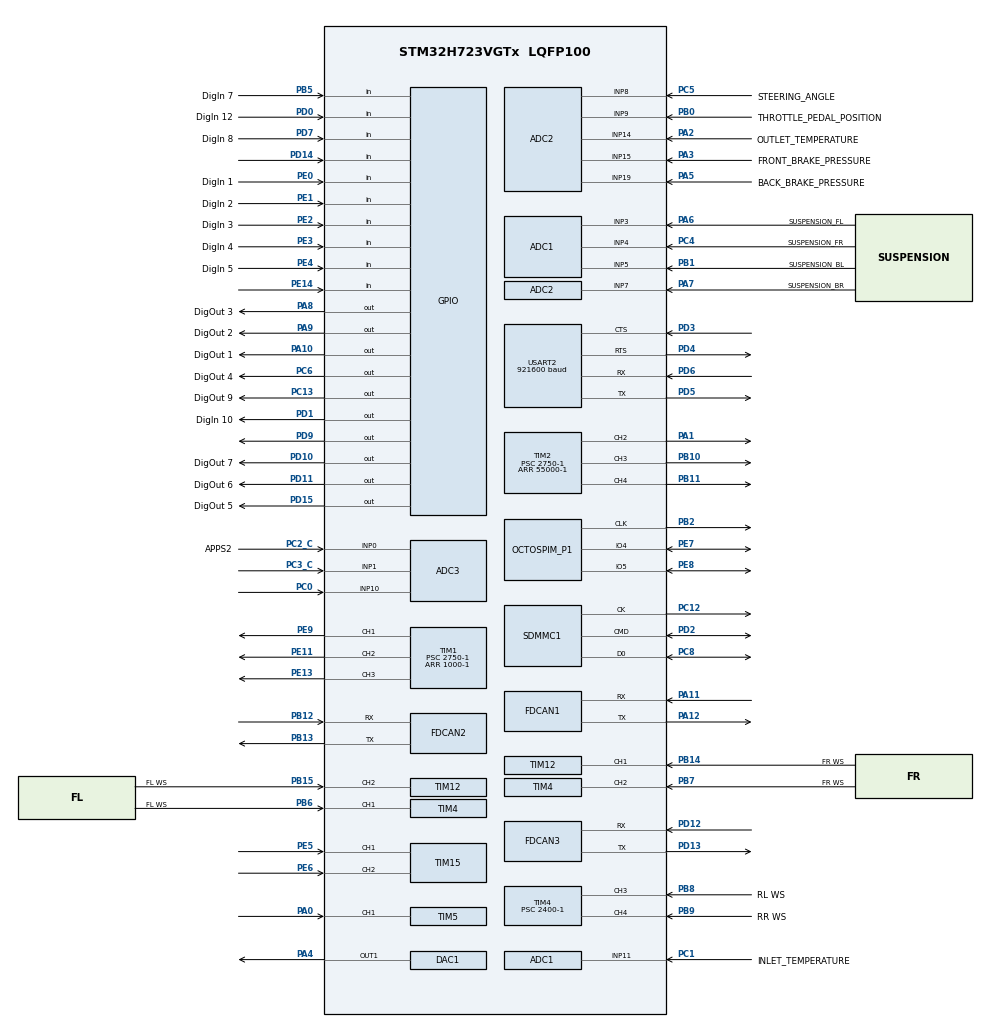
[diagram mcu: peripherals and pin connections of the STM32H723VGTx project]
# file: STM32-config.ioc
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ADC1.Channel-0\#ChannelRegularConversion=ADC_CHANNEL_3
ADC1.Channel-1\#ChannelRegularConversion=ADC_CHANNEL_4
ADC1.Channel-2\#ChannelRegularConversion=ADC_CHANNEL_5
ADC1.Channel-3\#ChannelRegularConversion=ADC_CHANNEL_7
ADC1.Channel-4\#ChannelRegularConversion=ADC_CHANNEL_8
ADC1.Channel-5\#ChannelRegularConversion=ADC_CHANNEL_9
ADC1.Channel-6\#ChannelRegularConversion=ADC_CHANNEL_11
ADC1.Channel-7\#ChannelRegularConversion=ADC_CHANNEL_14
ADC1.Channel-8\#ChannelRegularConversion=ADC_CHANNEL_15
ADC1.Channel-9\#ChannelRegularConversion=ADC_CHANNEL_19
ADC1.ClockPrescaler=ADC_CLOCK_SYNC_PCLK_DIV4
ADC1.ContinuousConvMode=DISABLE
ADC1.ConversionDataManagement=ADC_CONVERSIONDATA_DMA_ONESHOT
ADC1.DMAAccessModeView=ENABLE
ADC1.ExternalTrigConv=ADC_EXTERNALTRIG_T1_TRGO
ADC1.Mode=ADC_DUALMODE_REGSIMULT
ADC1.NbrOfConversion=10
ADC1.NbrOfConversionFlag=1
ADC1.OffsetNumber-0\#ChannelRegularConversion=ADC_OFFSET_NONE
ADC1.OffsetNumber-1\#ChannelRegularConversion=ADC_OFFSET_NONE
ADC1.OffsetNumber-2\#ChannelRegularConversion=ADC_OFFSET_NONE
ADC1.OffsetNumber-3\#ChannelRegularConversion=ADC_OFFSET_NONE
ADC1.OffsetNumber-4\#ChannelRegularConversion=ADC_OFFSET_NONE
ADC1.OffsetNumber-5\#ChannelRegularConversion=ADC_OFFSET_NONE
ADC1.OffsetNumber-6\#ChannelRegularConversion=ADC_OFFSET_NONE
ADC1.OffsetNumber-7\#ChannelRegularConversion=ADC_OFFSET_NONE
ADC1.OffsetNumber-8\#ChannelRegularConversion=ADC_OFFSET_NONE
ADC1.OffsetNumber-9\#ChannelRegularConversion=ADC_OFFSET_NONE
ADC1.OffsetSignedSaturation-0\#ChannelRegularConversion=DISABLE
ADC1.OffsetSignedSaturation-1\#ChannelRegularConversion=DISABLE
ADC1.OffsetSignedSaturation-2\#ChannelRegularConversion=DISABLE
ADC1.OffsetSignedSaturation-3\#ChannelRegularConversion=DISABLE
ADC1.OffsetSignedSaturation-4\#ChannelRegularConversion=DISABLE
ADC1.OffsetSignedSaturation-5\#ChannelRegularConversion=DISABLE
ADC1.OffsetSignedSaturation-6\#ChannelRegularConversion=DISABLE
ADC1.OffsetSignedSaturation-7\#ChannelRegularConversion=DISABLE
ADC1.OffsetSignedSaturation-8\#ChannelRegularConversion=DISABLE
ADC1.OffsetSignedSaturation-9\#ChannelRegularConversion=DISABLE
ADC1.OversamplingMode=DISABLE
ADC1.Rank-0\#ChannelRegularConversion=1
ADC1.Rank-1\#ChannelRegularConversion=2
ADC1.Rank-2\#ChannelRegularConversion=3
ADC1.Rank-3\#ChannelRegularConversion=4
ADC1.Rank-4\#ChannelRegularConversion=5
ADC1.Rank-5\#ChannelRegularConversion=6
ADC1.Rank-6\#ChannelRegularConversion=7
ADC1.Rank-7\#ChannelRegularConversion=8
ADC1.Rank-8\#ChannelRegularConversion=9
ADC1.Rank-9\#ChannelRegularConversion=10
ADC1.Ratio=1
ADC1.SamplingTime-0\#ChannelRegularConversion=ADC_SAMPLETIME_387CYCLES_5
ADC1.SamplingTime-1\#ChannelRegularConversion=ADC_SAMPLETIME_387CYCLES_5
ADC1.SamplingTime-2\#ChannelRegularConversion=ADC_SAMPLETIME_387CYCLES_5
ADC1.SamplingTime-3\#ChannelRegularConversion=ADC_SAMPLETIME_387CYCLES_5
ADC1.SamplingTime-4\#ChannelRegularConversion=ADC_SAMPLETIME_387CYCLES_5
ADC1.SamplingTime-5\#ChannelRegularConversion=ADC_SAMPLETIME_387CYCLES_5
ADC1.SamplingTime-6\#ChannelRegularConversion=ADC_SAMPLETIME_387CYCLES_5
ADC1.SamplingTime-7\#ChannelRegularConversion=ADC_SAMPLETIME_387CYCLES_5
ADC1.SamplingTime-8\#ChannelRegularConversion=ADC_SAMPLETIME_387CYCLES_5
ADC1.SamplingTime-9\#ChannelRegularConversion=ADC_SAMPLETIME_387CYCLES_5
ADC1.master=1
ADC2.Channel-0\#ChannelRegularConversion=ADC_CHANNEL_3
ADC2.Channel-1\#ChannelRegularConversion=ADC_CHANNEL_4
ADC2.Channel-2\#ChannelRegularConversion=ADC_CHANNEL_5
ADC2.Channel-3\#ChannelRegularConversion=ADC_CHANNEL_7
ADC2.Channel-4\#ChannelRegularConversion=ADC_CHANNEL_8
ADC2.Channel-5\#ChannelRegularConversion=ADC_CHANNEL_9
ADC2.Channel-6\#ChannelRegularConversion=ADC_CHANNEL_11
ADC2.Channel-7\#ChannelRegularConversion=ADC_CHANNEL_14
ADC2.Channel-8\#ChannelRegularConversion=ADC_CHANNEL_15
ADC2.Channel-9\#ChannelRegularConversion=ADC_CHANNEL_19
ADC2.ClockPrescaler=ADC_CLOCK_SYNC_PCLK_DIV4
ADC2.ContinuousConvMode=DISABLE
ADC2.ConversionDataManagement=ADC_CONVERSIONDATA_DR
ADC2.DMAAccessModeView=ENABLE
ADC2.Mode=ADC_DUALMODE_REGSIMULT
ADC2.NbrOfConversion=10
ADC2.NbrOfConversionFlag=1
ADC2.OffsetNumber-0\#ChannelRegularConversion=ADC_OFFSET_NONE
ADC2.OffsetNumber-1\#ChannelRegularConversion=ADC_OFFSET_NONE
ADC2.OffsetNumber-2\#ChannelRegularConversion=ADC_OFFSET_NONE
ADC2.OffsetNumber-3\#ChannelRegularConversion=ADC_OFFSET_NONE
ADC2.OffsetNumber-4\#ChannelRegularConversion=ADC_OFFSET_NONE
ADC2.OffsetNumber-5\#ChannelRegularConversion=ADC_OFFSET_NONE
ADC2.OffsetNumber-6\#ChannelRegularConversion=ADC_OFFSET_NONE
ADC2.OffsetNumber-7\#ChannelRegularConversion=ADC_OFFSET_NONE
ADC2.OffsetNumber-8\#ChannelRegularConversion=ADC_OFFSET_NONE
ADC2.OffsetNumber-9\#ChannelRegularConversion=ADC_OFFSET_NONE
ADC2.OffsetSignedSaturation-0\#ChannelRegularConversion=DISABLE
ADC2.OffsetSignedSaturation-1\#ChannelRegularConversion=DISABLE
ADC2.OffsetSignedSaturation-2\#ChannelRegularConversion=DISABLE
ADC2.OffsetSignedSaturation-3\#ChannelRegularConversion=DISABLE
ADC2.OffsetSignedSaturation-4\#ChannelRegularConversion=DISABLE
ADC2.OffsetSignedSaturation-5\#ChannelRegularConversion=DISABLE
ADC2.OffsetSignedSaturation-6\#ChannelRegularConversion=DISABLE
ADC2.OffsetSignedSaturation-7\#ChannelRegularConversion=DISABLE
ADC2.OffsetSignedSaturation-8\#ChannelRegularConversion=DISABLE
ADC2.OffsetSignedSaturation-9\#ChannelRegularConversion=DISABLE
ADC2.Rank-0\#ChannelRegularConversion=1
ADC2.Rank-1\#ChannelRegularConversion=2
ADC2.Rank-2\#ChannelRegularConversion=3
ADC2.Rank-3\#ChannelRegularConversion=4
ADC2.Rank-4\#ChannelRegularConversion=5
ADC2.Rank-5\#ChannelRegularConversion=6
ADC2.Rank-6\#ChannelRegularConversion=7
ADC2.Rank-7\#ChannelRegularConversion=8
ADC2.Rank-8\#ChannelRegularConversion=9
ADC2.Rank-9\#ChannelRegularConversion=10
ADC2.SamplingTime-0\#ChannelRegularConversion=ADC_SAMPLETIME_387CYCLES_5
ADC2.SamplingTime-1\#ChannelRegularConversion=ADC_SAMPLETIME_387CYCLES_5
ADC2.SamplingTime-2\#ChannelRegularConversion=ADC_SAMPLETIME_387CYCLES_5
ADC2.SamplingTime-3\#ChannelRegularConversion=ADC_SAMPLETIME_387CYCLES_5
ADC2.SamplingTime-4\#ChannelRegularConversion=ADC_SAMPLETIME_387CYCLES_5
ADC2.SamplingTime-5\#ChannelRegularConversion=ADC_SAMPLETIME_387CYCLES_5
ADC2.SamplingTime-6\#ChannelRegularConversion=ADC_SAMPLETIME_387CYCLES_5
ADC2.SamplingTime-7\#ChannelRegularConversion=ADC_SAMPLETIME_387CYCLES_5
ADC2.SamplingTime-8\#ChannelRegularConversion=ADC_SAMPLETIME_387CYCLES_5
ADC2.SamplingTime-9\#ChannelRegularConversion=ADC_SAMPLETIME_387CYCLES_5
ADC3.Channel-0\#ChannelRegularConversion=ADC_CHANNEL_0
ADC3.ClockPrescaler=ADC_CLOCK_SYNC_PCLK_DIV4
ADC3.ConversionDataManagement=ADC_CONVERSIONDATA_DMA_ONESHOT
ADC3.ExternalTrigConv=ADC_EXTERNALTRIG_T1_TRGO
ADC3.NbrOfConversion=1
ADC3.NbrOfConversionFlag=1
ADC3.OffsetNumber-0\#ChannelRegularConversion=ADC_OFFSET_NONE
ADC3.OffsetSign-0\#ChannelRegularConversion=ADC3_OFFSET_SIGN_NEGATIVE
ADC3.Rank-0\#ChannelRegularConversion=1
ADC3.SamplingTime-0\#ChannelRegularConversion=ADC3_SAMPLETIME_247CYCLES_5
Bdma.ADC3.0.Direction=DMA_PERIPH_TO_MEMORY
Bdma.ADC3.0.EventEnable=DISABLE
Bdma.ADC3.0.Instance=BDMA_Channel0
Bdma.ADC3.0.MemDataAlignment=DMA_MDATAALIGN_HALFWORD
Bdma.ADC3.0.MemInc=DMA_MINC_ENABLE
Bdma.ADC3.0.Mode=DMA_NORMAL
Bdma.ADC3.0.PeriphDataAlignment=DMA_PDATAALIGN_HALFWORD
Bdma.ADC3.0.PeriphInc=DMA_PINC_DISABLE
Bdma.ADC3.0.Polarity=HAL_DMAMUX_REQ_GEN_RISING
Bdma.ADC3.0.Priority=DMA_PRIORITY_LOW
Bdma.ADC3.0.RequestNumber=1
Bdma.ADC3.0.SignalID=NONE
Bdma.ADC3.0.SyncEnable=DISABLE
Bdma.ADC3.0.SyncPolarity=HAL_DMAMUX_SYNC_NO_EVENT
Bdma.ADC3.0.SyncRequestNumber=1
Bdma.ADC3.0.SyncSignalID=NONE
Bdma.Request0=ADC3
Bdma.RequestsNb=1
CORTEX_M7.AccessPermission_Spec=MPU_REGION_FULL_ACCESS
CORTEX_M7.IsCacheable_Spec=MPU_ACCESS_CACHEABLE
CORTEX_M7.default_mode_Activation=1
DAC1.DAC_Channel-DAC_OUT1=DAC_CHANNEL_1
Dma.ADC1.0.Direction=DMA_PERIPH_TO_MEMORY
Dma.ADC1.0.EventEnable=DISABLE
Dma.ADC1.0.FIFOMode=DMA_FIFOMODE_DISABLE
Dma.ADC1.0.Instance=DMA1_Stream0
Dma.ADC1.0.MemDataAlignment=DMA_MDATAALIGN_WORD
Dma.ADC1.0.MemInc=DMA_MINC_ENABLE
Dma.ADC1.0.Mode=DMA_NORMAL
Dma.ADC1.0.PeriphDataAlignment=DMA_PDATAALIGN_WORD
Dma.ADC1.0.PeriphInc=DMA_PINC_DISABLE
Dma.ADC1.0.Polarity=HAL_DMAMUX_REQ_GEN_RISING
Dma.ADC1.0.Priority=DMA_PRIORITY_LOW
Dma.ADC1.0.RequestNumber=1
Dma.ADC1.0.SignalID=NONE
Dma.ADC1.0.SyncEnable=DISABLE
Dma.ADC1.0.SyncPolarity=HAL_DMAMUX_SYNC_NO_EVENT
Dma.ADC1.0.SyncRequestNumber=1
Dma.ADC1.0.SyncSignalID=NONE
Dma.Request0=ADC1
Dma.Request1=USART2_TX
Dma.Request2=USART2_RX
Dma.USART2_RX.2.Direction=DMA_PERIPH_TO_MEMORY
Dma.USART2_RX.2.EventEnable=DISABLE
Dma.USART2_RX.2.FIFOMode=DMA_FIFOMODE_DISABLE
Dma.USART2_RX.2.Instance=DMA2_Stream1
Dma.USART2_RX.2.MemDataAlignment=DMA_MDATAALIGN_BYTE
Dma.USART2_RX.2.MemInc=DMA_MINC_ENABLE
Dma.USART2_RX.2.Mode=DMA_NORMAL
Dma.USART2_RX.2.PeriphDataAlignment=DMA_PDATAALIGN_BYTE
Dma.USART2_RX.2.PeriphInc=DMA_PINC_DISABLE
Dma.USART2_RX.2.Polarity=HAL_DMAMUX_REQ_GEN_RISING
Dma.USART2_RX.2.Priority=DMA_PRIORITY_LOW
Dma.USART2_RX.2.RequestNumber=1
Dma.USART2_RX.2.SignalID=NONE
Dma.USART2_RX.2.SyncEnable=DISABLE
Dma.USART2_RX.2.SyncPolarity=HAL_DMAMUX_SYNC_NO_EVENT
Dma.USART2_RX.2.SyncRequestNumber=1
Dma.USART2_RX.2.SyncSignalID=NONE
Dma.USART2_TX.1.Direction=DMA_MEMORY_TO_PERIPH
Dma.USART2_TX.1.EventEnable=DISABLE
Dma.USART2_TX.1.FIFOMode=DMA_FIFOMODE_DISABLE
Dma.USART2_TX.1.Instance=DMA2_Stream0
Dma.USART2_TX.1.MemDataAlignment=DMA_MDATAALIGN_BYTE
Dma.USART2_TX.1.MemInc=DMA_MINC_ENABLE
Dma.USART2_TX.1.Mode=DMA_CIRCULAR
Dma.USART2_TX.1.PeriphDataAlignment=DMA_PDATAALIGN_BYTE
Dma.USART2_TX.1.PeriphInc=DMA_PINC_DISABLE
Dma.USART2_TX.1.Polarity=HAL_DMAMUX_REQ_GEN_RISING
Dma.USART2_TX.1.Priority=DMA_PRIORITY_LOW
Dma.USART2_TX.1.RequestNumber=1
Dma.USART2_TX.1.SignalID=NONE
Dma.USART2_TX.1.SyncEnable=DISABLE
Dma.USART2_TX.1.SyncPolarity=HAL_DMAMUX_SYNC_NO_EVENT
Dma.USART2_TX.1.SyncRequestNumber=1
Dma.USART2_TX.1.SyncSignalID=NONE
FATFS.BSP.number=1
FATFS._FS_EXFAT=1
FATFS._FS_RPATH=1
FATFS._MAX_SS=512
FATFS._MIN_SS=512
FATFS._USE_CHMOD=1
FATFS._USE_EXPAND=1
FATFS._USE_FIND=1
FATFS._USE_FORWARD=1
FATFS._USE_LABEL=1
FATFS._USE_LFN=2
FATFS0.BSP.STBoard=false
FATFS0.BSP.api=Unknown
FATFS0.BSP.instance=PE14
FATFS0.BSP.ip=GPIO
FATFS0.BSP.mode=Input
FATFS0.BSP.name=Detect_SDIO
FATFS0.BSP.solution=PE14
FDCAN1.AutoRetransmission=ENABLE
FDCAN1.CalculateBaudRateNominal=500000
FDCAN1.CalculateTimeBitNominal=2000
FDCAN1.CalculateTimeQuantumNominal=125.0
FDCAN1.NominalPrescaler=10
FDCAN1.NominalTimeSeg1=13
FDCAN1.NominalTimeSeg2=2
FDCAN1.RxFifo0ElmtsNbr=16
FDCAN1.RxFifo1ElmtsNbr=32
FDCAN1.TxBuffersNbr=0
FDCAN1.TxFifoQueueElmtsNbr=16
FDCAN1.TxFifoQueueMode=FDCAN_TX_QUEUE_OPERATION
FDCAN2.AutoRetransmission=ENABLE
FDCAN2.CalculateBaudRateNominal=1000000
FDCAN2.CalculateTimeBitNominal=1000
FDCAN2.CalculateTimeQuantumNominal=62.5
FDCAN2.MessageRAMOffset=256
FDCAN2.NominalPrescaler=5
FDCAN2.NominalTimeSeg1=13
FDCAN2.NominalTimeSeg2=2
FDCAN2.RxFifo0ElmtsNbr=32
FDCAN2.RxFifo1ElmtsNbr=32
FDCAN2.TxBuffersNbr=0
FDCAN2.TxFifoQueueElmtsNbr=16
FDCAN3.CalculateBaudRateNominal=1666666
FDCAN3.CalculateTimeBitNominal=600
FDCAN3.CalculateTimeQuantumNominal=200.0
FDCAN3.MessageRAMOffset=1024
FDCAN3.TxBuffersNbr=32
FREERTOS.BinarySemaphores01=CAN1rxS,Static,CAN1rxSControlBlock,Available;CAN1txS,Static,CAN1txSControlBlock,Available;CAN2rxS,Static,CAN2rxSControlBlock,Available;CAN2txS,Static,CAN2txSControlBlock,Available
FREERTOS.Events01=VCUGroupEvent,Static,VCUGroupEventControlBlock;RTD,Static,RTDControlBlock
FREERTOS.Mutexes01=CAN1txM,Static,CAN1txMControlBlock,Available;CAN2txM,Static,CAN2txMControlBlock,Available
FREERTOS.Queues01=CAN1rxQ,16,CAN_Msg_Raw,0,Static,CAN1rxQBuffer,CAN1rxQControlBlock;CAN1txQ,8,CAN_Msg_Raw,0,Static,CAN1txQBuffer,CAN1txQControlBlock;CAN2rxQ,24,CAN_Msg_Raw,0,Static,CAN2rxQBuffer,CAN2rxQControlBlock;CAN2txQ,16,CAN_Msg_Raw,0,Static,CAN2txQBuffer,CAN2txQControlBlock;ADCLogQ,64,TelemetryData_t,0,Static,ADCLogQBuffer,ADCLogQControlBlock;CANLogQ,16,TelemetryData_t,0,Static,CANLogQBuffer,CANLogQControlBlock
FREERTOS.Tasks01=defaultTask,24,128,StartDefaultTask,Default,NULL,Dynamic,NULL,NULL;ADCTask,35,256,StartADCTask,Default,NULL,Static,ADCTaskBuffer,ADCTaskControlBlock;DecodeCAN2,18,1024,StartDecodeCAN2,Default,NULL,Static,DecodeCAN2Buffer,DecodeCAN2ControlBlock;DecodeCAN1,37,1024,StartDecodeCAN1,Default,NULL,Static,DecodeCAN1Buffer,DecodeCAN1ControlBlock;CreateMsgCAN1,36,1024,StartCreateMsgCAN1,Default,NULL,Static,CreateMsgCAN1Buffer,CreateMsgCAN1ControlBlock;CreateMsgCAN2,8,1024,StartCreateMsgCAN2,Default,NULL,Static,CreateMsgCAN2Buffer,CreateMsgCAN2ControlBlock;PWMTask,28,128,StartPWMTask,Default,NULL,Static,PWMTaskBuffer,PWMTaskControlBlock;LoggingTask,9,1024,StartLoggingTask,Default,NULL,Static,LoggingTaskBuffer,LoggingTaskControlBlock;GPIOTask,27,128,StartTaskGPIO,Default,NULL,Static,GPIOTaskBuffer,GPIOTaskControlBlock;RTDSM,55,128,StartRTDSM,Default,NULL,Static,RTDSMBuffer,RTDSMControlBlock;RTDOn,53,128,StartRTDOn,Default,NULL,Static,RTDOnBuffer,RTDOnControlBlock;TelemLog,8,256,StartTelemLog,Default,NULL,Static,TelemLogBuffer,TelemLogControlBlock
FREERTOS.configUSE_NEWLIB_REENTRANT=1
Mcu.Family=STM32H7
Mcu.Name=STM32H723VGTx
Mcu.Package=LQFP100
Mdma.MDMA_Channel0.Request0=SW
Mdma.MDMA_Channel0.RequestsNb=1
Mdma.MDMA_Channel0.SW.0.BlockCount=0
Mdma.MDMA_Channel0.SW.0.BlockDataLength=0
Mdma.MDMA_Channel0.SW.0.BufferTransferLength=1
Mdma.MDMA_Channel0.SW.0.CircularMode=MDMA_LINEAR_LIST
Mdma.MDMA_Channel0.SW.0.DataAlignment=MDMA_DATAALIGN_PACKENABLE
Mdma.MDMA_Channel0.SW.0.DestBlockAddressOffset=0
Mdma.MDMA_Channel0.SW.0.DestBurst=MDMA_DEST_BURST_SINGLE
Mdma.MDMA_Channel0.SW.0.DestDataSize=MDMA_DEST_DATASIZE_BYTE
Mdma.MDMA_Channel0.SW.0.DestinationInc=MDMA_DEST_INC_BYTE
Mdma.MDMA_Channel0.SW.0.DstAddress=0
Mdma.MDMA_Channel0.SW.0.Endianness=MDMA_LITTLE_ENDIANNESS_PRESERVE
Mdma.MDMA_Channel0.SW.0.Instance=MDMA_Channel0
Mdma.MDMA_Channel0.SW.0.MaskAddress=0
Mdma.MDMA_Channel0.SW.0.MaskData=0
Mdma.MDMA_Channel0.SW.0.Priority=MDMA_PRIORITY_LOW
Mdma.MDMA_Channel0.SW.0.Rank=First
Mdma.MDMA_Channel0.SW.0.SourceBlockAddressOffset=0
Mdma.MDMA_Channel0.SW.0.SourceBurst=MDMA_SOURCE_BURST_SINGLE
Mdma.MDMA_Channel0.SW.0.SourceDataSize=MDMA_SRC_DATASIZE_BYTE
Mdma.MDMA_Channel0.SW.0.SourceInc=MDMA_SRC_INC_BYTE
Mdma.MDMA_Channel0.SW.0.SrcAddress=0
Mdma.MDMA_Channel0.SW.0.TransferTriggerMode=MDMA_BUFFER_TRANSFER
Mdma.RequestSet0=MDMA_Channel0
Mdma.RequestSetsNb=1
NVIC.ADC3_IRQn=true\:5\:0\:false\:false\:true\:true\:true\:true\:true
NVIC.ADC_IRQn=true\:5\:0\:false\:false\:true\:true\:true\:true\:true
NVIC.BDMA_Channel0_IRQn=true\:5\:0\:false\:false\:true\:true\:false\:true\:true
NVIC.DMA1_Stream0_IRQn=true\:5\:0\:false\:false\:true\:true\:false\:true\:true
NVIC.DMA2_Stream0_IRQn=true\:5\:0\:false\:false\:true\:false\:false\:true\:true
NVIC.DMA2_Stream1_IRQn=true\:5\:0\:false\:false\:true\:false\:false\:true\:true
NVIC.FDCAN1_IT0_IRQn=true\:5\:0\:false\:false\:true\:true\:true\:true\:true
NVIC.FDCAN2_IT0_IRQn=true\:5\:0\:false\:false\:true\:true\:true\:true\:true
NVIC.FDCAN2_IT1_IRQn=true\:5\:0\:false\:false\:true\:true\:true\:true\:true
NVIC.MDMA_IRQn=true\:5\:0\:false\:false\:true\:true\:false\:true\:true
NVIC.PriorityGroup=NVIC_PRIORITYGROUP_4
NVIC.SDMMC1_IRQn=true\:5\:0\:false\:false\:true\:true\:true\:true\:true
NVIC.TIM17_IRQn=true\:15\:0\:false\:false\:true\:false\:false\:true\:true
NVIC.TIM2_IRQn=true\:5\:0\:false\:false\:true\:true\:true\:true\:true
NVIC.TIM4_IRQn=true\:5\:0\:false\:false\:true\:true\:true\:true\:true
NVIC.TIM6_DAC_IRQn=true\:5\:0\:false\:false\:true\:false\:false\:true\:true
NVIC.TIM8_UP_TIM13_IRQn=true\:5\:0\:false\:false\:true\:true\:true\:true\:true
NVIC.TimeBase=TIM17_IRQn
NVIC.TimeBaseIP=TIM17
PA0.Signal=S_TIM5_CH1
PA1.Signal=S_TIM2_CH2
PA10.GPIO_Label=DigOut 1
PA10.Signal=GPIO_Output
PA11.Mode=FDCAN_Activate
PA11.Signal=FDCAN1_RX
PA12.Mode=FDCAN_Activate
PA12.Signal=FDCAN1_TX
PA13(JTMS/SWDIO).Mode=JTAG_5_pins
PA13(JTMS/SWDIO).Signal=DEBUG_JTMS-SWDIO
PA14(JTCK/SWCLK).Mode=JTAG_5_pins
PA14(JTCK/SWCLK).Signal=DEBUG_JTCK-SWCLK
PA15(JTDI).Mode=JTAG_5_pins
PA15(JTDI).Signal=DEBUG_JTDI
PA2.GPIO_Label=OUTLET_TEMPERATURE
PA2.GPIO_Pd=GPIO_PULLDOWN
PA2.Signal=ADCx_INP14
PA3.GPIO_Label=FRONT_BRAKE_PRESSURE
PA3.GPIO_Pd=GPIO_PULLDOWN
PA3.Signal=ADCx_INP15
PA4.Signal=COMP_DAC11_group
PA5.GPIO_Label=BACK_BRAKE_PRESSURE
PA5.GPIO_Pd=GPIO_PULLDOWN
PA5.Signal=ADCx_INP19
PA6.GPIO_Label=SUSPENSION_FL
PA6.GPIO_Pd=GPIO_PULLDOWN
PA6.Signal=ADCx_INP3
PA7.GPIO_Label=SUSPENSION_BR
PA7.GPIO_Pd=GPIO_PULLDOWN
PA7.Signal=ADCx_INP7
PA8.GPIO_Label=DigOut 3
PA8.Signal=GPIO_Output
PA9.GPIO_Label=DigOut 2
PA9.Signal=GPIO_Output
PB0.GPIO_Label=THROTTLE_PEDAL_POSITION
PB0.GPIO_Pd=GPIO_PULLDOWN
PB0.Signal=ADCx_INP9
PB1.GPIO_Label=SUSPENSION_BL
PB1.GPIO_Pd=GPIO_PULLDOWN
PB1.Signal=ADCx_INP5
PB10.Signal=S_TIM2_CH3
PB11.Signal=S_TIM2_CH4
PB12.Mode=FDCAN_Activate
PB12.Signal=FDCAN2_RX
PB13.Mode=FDCAN_Activate
PB13.Signal=FDCAN2_TX
PB14.GPIO_Label=FR WS
PB14.Signal=S_TIM12_CH1
PB15.GPIO_Label=FL WS
PB15.Signal=S_TIM12_CH2
PB2.Mode=O1_P1_CLK
PB2.Signal=OCTOSPIM_P1_CLK
PB3(JTDO/TRACESWO).Mode=JTAG_5_pins
PB3(JTDO/TRACESWO).Signal=DEBUG_JTDO-SWO
PB4(NJTRST).Mode=JTAG_5_pins
PB4(NJTRST).Signal=DEBUG_JTRST
PB5.GPIO_Label=DigIn 7
PB5.Signal=GPIO_Input
PB6.GPIO_Label=FL WS
PB6.GPIO_PuPd=GPIO_PULLUP
PB6.Signal=S_TIM4_CH1
PB7.GPIO_Label=FR WS
PB7.GPIO_PuPd=GPIO_PULLUP
PB7.Signal=S_TIM4_CH2
PB8.GPIO_Label=RL WS
PB8.GPIO_PuPd=GPIO_PULLUP
PB8.Signal=S_TIM4_CH3
PB9.GPIO_Label=RR WS
PB9.GPIO_PuPd=GPIO_PULLUP
PB9.Signal=S_TIM4_CH4
PC0.Signal=ADCx_INP10
PC1.GPIO_Label=INLET_TEMPERATURE
PC1.GPIO_Pd=GPIO_PULLDOWN
PC1.Signal=ADCx_INP11
PC10.Signal=SDMMC1_D2
PC11.Signal=SDMMC1_D3
PC12.Mode=SD_1_bit
PC12.Signal=SDMMC1_CK
PC13.GPIO_Label=DigOut 9
PC13.Signal=GPIO_Output
PC2_C.GPIO_Label=APPS2
PC2_C.Mode=IN0-Single-Ended
PC2_C.Signal=ADC3_INP0
PC3_C.Mode=IN1-Single-Ended
PC3_C.Signal=ADC3_INP1
PC4.GPIO_Label=SUSPENSION_FR
PC4.GPIO_Pd=GPIO_PULLDOWN
PC4.Signal=ADCx_INP4
PC5.GPIO_Label=STEERING_ANGLE
PC5.GPIO_Pd=GPIO_PULLDOWN
PC5.Signal=ADCx_INP8
PC6.GPIO_Label=DigOut 4
PC6.Signal=GPIO_Output
PC7.Mode=External_Trigger_bidirectional
PC7.Signal=DEBUG_TRGIO
PC8.GPIO_PuPd=GPIO_PULLUP
PC8.Mode=SD_1_bit
PC8.Signal=SDMMC1_D0
PC9.Signal=SDMMC1_D1
PD0.GPIO_Label=DigIn 12
PD0.Signal=GPIO_Input
PD1.GPIO_Label=DigIn 10
PD1.Signal=GPIO_Output
PD10.GPIO_Label=DigOut 7
PD10.Signal=GPIO_Output
PD11.GPIO_Label=DigOut 6
PD11.Signal=GPIO_Output
PD12.Mode=FDCAN_Activate
PD12.Signal=FDCAN3_RX
PD13.Mode=FDCAN_Activate
PD13.Signal=FDCAN3_TX
PD14.Signal=GPIO_Input
PD15.GPIO_Label=DigOut 5
PD15.Signal=GPIO_Output
PD2.GPIO_PuPd=GPIO_PULLUP
PD2.GPIO_Speed_High_Default=GPIO_SPEED_FREQ_MEDIUM
PD2.Mode=SD_1_bit
PD2.Signal=SDMMC1_CMD
PD3.Mode=CTS_RTS
PD3.Signal=USART2_CTS
PD4.Mode=CTS_RTS
PD4.Signal=USART2_RTS
PD5.Mode=Asynchronous
PD5.Signal=USART2_TX
PD6.Mode=Asynchronous
PD6.Signal=USART2_RX
PD7.GPIO_Label=DigIn 8
PD7.Signal=GPIO_Input
PD9.Signal=GPIO_Output
PE0.GPIO_Label=DigIn 1
PE0.Signal=GPIO_Input
PE1.GPIO_Label=DigIn 2
PE1.Signal=GPIO_Input
PE11.Signal=S_TIM1_CH2
PE13.Signal=S_TIM1_CH3
PE14.GPIO_PuPd=GPIO_PULLDOWN
PE14.Signal=GPIO_Input
PE2.GPIO_Label=DigIn 3
PE2.Signal=GPIO_Input
PE3.GPIO_Label=DigIn 4
PE3.Signal=GPIO_Input
PE4.GPIO_Label=DigIn 5
PE4.Signal=GPIO_Input
PE5.Signal=S_TIM15_CH1
PE6.Signal=S_TIM15_CH2
PE7.Mode=OCTOSPI1_IOL_Port1H_54
PE7.Signal=OCTOSPIM_P1_IO4
PE8.Mode=OCTOSPI1_IOL_Port1H_54
PE8.Signal=OCTOSPIM_P1_IO5
PE9.Signal=S_TIM1_CH1
PH0-OSC_IN.Mode=HSE-External-Oscillator
PH0-OSC_IN.Signal=RCC_OSC_IN
PH1-OSC_OUT.Mode=HSE-External-Oscillator
PH1-OSC_OUT.Signal=RCC_OSC_OUT
ProjectManager.HeapSize=0x200
ProjectManager.StackSize=0x400
ProjectManager.TargetToolchain=CMake
RAMECC.Instance-RAMECC1_Monitor1=RAMECC1_Monitor1
RCC.ADCFreq_Value=96000000
RCC.APB1Freq_Value=120000000
RCC.APB2Freq_Value=120000000
RCC.APB3Freq_Value=120000000
RCC.APB4Freq_Value=120000000
RCC.CortexFreq_Value=240000000
RCC.D1PPRE=RCC_APB3_DIV2
RCC.D2PPRE1=RCC_APB1_DIV2
RCC.D2PPRE2=RCC_APB2_DIV2
RCC.D3PPRE=RCC_APB4_DIV2
RCC.DIVM1=4
RCC.DIVM2=4
RCC.DIVN1=15
RCC.DIVN2=12
RCC.DIVP1=1
RCC.DIVQ1=3
RCC.HCLKFreq_Value=240000000
RCC.HSE_VALUE=25000000
RCC.PLL2FRACN=0
RCC.PLLFRACN=0
RCC.SYSCLKFreq_VALUE=240000000
RCC.SYSCLKSource=RCC_SYSCLKSOURCE_PLLCLK
RCC.USBFreq_Value=80000000
RTC.Date=21
RTC.Month=RTC_MONTH_OCTOBER
RTC.WeekDay=RTC_WEEKDAY_WEDNESDAY
RTC.Year=26
SDMMC1.ClockDiv=4
SH.ADCx_INP10.0=ADC3_INP10,IN10-Single-Ended
SH.ADCx_INP11.0=ADC1_INP11,IN11-Single-Ended
SH.ADCx_INP11.1=ADC2_INP11,IN11-Single-Ended
SH.ADCx_INP14.0=ADC2_INP14,IN14-Single-Ended
SH.ADCx_INP14.1=ADC1_INP14,IN14-Single-Ended
SH.ADCx_INP15.0=ADC2_INP15,IN15-Single-Ended
SH.ADCx_INP15.1=ADC1_INP15,IN15-Single-Ended
SH.ADCx_INP19.0=ADC2_INP19,IN19-Single-Ended
SH.ADCx_INP19.1=ADC1_INP19,IN19-Single-Ended
SH.ADCx_INP3.0=ADC1_INP3,IN3-Single-Ended
SH.ADCx_INP3.1=ADC2_INP3,IN3-Single-Ended
SH.ADCx_INP4.0=ADC1_INP4,IN4-Single-Ended
SH.ADCx_INP4.1=ADC2_INP4,IN4-Single-Ended
SH.ADCx_INP5.0=ADC1_INP5,IN5-Single-Ended
SH.ADCx_INP5.1=ADC2_INP5,IN5-Single-Ended
SH.ADCx_INP7.0=ADC2_INP7,IN7-Single-Ended
SH.ADCx_INP7.1=ADC1_INP7,IN7-Single-Ended
SH.ADCx_INP8.0=ADC2_INP8,IN8-Single-Ended
SH.ADCx_INP8.1=ADC1_INP8,IN8-Single-Ended
SH.ADCx_INP9.0=ADC2_INP9,IN9-Single-Ended
SH.ADCx_INP9.1=ADC1_INP9,IN9-Single-Ended
SH.COMP_DAC11_group.0=DAC1_OUT1,DAC_OUT1
SH.S_TIM12_CH1.0=TIM12_CH1,Input_Capture1_from_TI1
SH.S_TIM12_CH2.0=TIM12_CH2,Input_Capture2_from_TI2
SH.S_TIM15_CH1.0=TIM15_CH1,Input_Capture1_from_TI1
SH.S_TIM15_CH2.0=TIM15_CH2,Input_Capture2_from_TI2
SH.S_TIM1_CH1.0=TIM1_CH1,PWM Generation1 CH1
SH.S_TIM1_CH2.0=TIM1_CH2,PWM Generation2 CH2
SH.S_TIM1_CH3.0=TIM1_CH3,PWM Generation3 CH3
SH.S_TIM2_CH2.0=TIM2_CH2,PWM Generation2 CH2
SH.S_TIM2_CH3.0=TIM2_CH3,PWM Generation3 CH3
SH.S_TIM2_CH4.0=TIM2_CH4,PWM Generation4 CH4
SH.S_TIM4_CH1.0=TIM4_CH1,Input_Capture1_from_TI1
SH.S_TIM4_CH2.0=TIM4_CH2,Input_Capture2_from_TI2
SH.S_TIM4_CH3.0=TIM4_CH3,Input_Capture3_from_TI3
SH.S_TIM4_CH4.0=TIM4_CH4,Input_Capture4_from_TI4
SH.S_TIM5_CH1.0=TIM5_CH1,Input_Capture1_from_TI1
TIM1.Channel-PWM\ Generation1\ CH1=TIM_CHANNEL_1
TIM1.Channel-PWM\ Generation2\ CH2=TIM_CHANNEL_2
TIM1.Channel-PWM\ Generation3\ CH3=TIM_CHANNEL_3
TIM1.Period=1000-1
TIM1.Prescaler=2750-1
TIM1.RepetitionCounter=1
TIM1.TIM_MasterOutputTrigger=TIM_TRGO_UPDATE
TIM12.Channel-Input_Capture1_from_TI1=TIM_CHANNEL_1
TIM12.Channel-Input_Capture2_from_TI2=TIM_CHANNEL_2
TIM12.Prescaler=2400-1
TIM15.Channel-Input_Capture1_from_TI1=TIM_CHANNEL_1
TIM15.Channel-Input_Capture2_from_TI2=TIM_CHANNEL_2
TIM15.TIM_MasterOutputTrigger=TIM_TRGO_RESET
TIM2.Channel-PWM\ Generation2\ CH2=TIM_CHANNEL_2
TIM2.Channel-PWM\ Generation3\ CH3=TIM_CHANNEL_3
TIM2.Channel-PWM\ Generation4\ CH4=TIM_CHANNEL_4
TIM2.Period=55000-1
TIM2.Prescaler=2750-1
TIM2.TIM_MasterOutputTrigger=TIM_TRGO_RESET
TIM2.TIM_MasterSlaveMode=TIM_MASTERSLAVEMODE_DISABLE
TIM23.Period=9999
TIM23.Prescaler=2749
TIM23.TIM_MasterOutputTrigger=TIM_TRGO_UPDATE
TIM23.TIM_MasterSlaveMode=TIM_MASTERSLAVEMODE_ENABLE
TIM24.Period=24999
TIM24.Prescaler=274
TIM24.TIM_MasterOutputTrigger=TIM_TRGO_UPDATE
TIM24.TIM_MasterSlaveMode=TIM_MASTERSLAVEMODE_ENABLE
TIM4.Channel-Input_Capture1_from_TI1=TIM_CHANNEL_1
TIM4.Channel-Input_Capture2_from_TI2=TIM_CHANNEL_2
TIM4.Channel-Input_Capture3_from_TI3=TIM_CHANNEL_3
TIM4.Channel-Input_Capture4_from_TI4=TIM_CHANNEL_4
TIM4.ICFilter_CH1=6
TIM4.ICFilter_CH2=6
TIM4.ICFilter_CH3=6
TIM4.ICFilter_CH4=6
TIM4.Prescaler=2400-1
TIM5.Channel-Input_Capture1_from_TI1=TIM_CHANNEL_1
TIM5.ICFilter_CH1=6
TIM5.Period=2000000-1
TIM5.Prescaler=240-1
USART2.BaudRate=921600
USART2.Parity=PARITY_EVEN
USART2.VirtualMode-Asynchronous=VM_ASYNC
VP_FATFS_VS_SDIO.Mode=SDIO
VP_FREERTOS_VS_CMSIS_V2.Mode=CMSIS_V2
VP_MEMORYMAP_VS_MEMORYMAP.Mode=CurAppReg
VP_OCTOSPI1_VS_dual.Mode=single_mode
VP_RAMECC_VS_D1_1.Mode=RAMECC1_Monitor1
VP_RTC_VS_RTC_Activate.Mode=RTC_Enabled
VP_RTC_VS_RTC_Calendar.Mode=RTC_Calendar
VP_SYS_VS_tim17.Mode=TIM17
VP_TIM13_VS_ClockSourceINT.Mode=Enable_Timer
VP_TIM14_VS_ClockSourceINT.Mode=Enable_Timer
VP_TIM23_VS_ClockSourceINT.Mode=Internal
VP_TIM24_VS_ClockSourceINT.Mode=Internal
VP_TIM4_VS_ClockSourceINT.Mode=Internal
VP_TIM5_VS_ClockSourceINT.Mode=Internal
board=custom

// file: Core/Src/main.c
/* USER CODE BEGIN Header */
/**
  ******************************************************************************
  * @file           : main.c
  * @brief          : Main program body
  ******************************************************************************
  * @attention
  *
  * Copyright (c) 2026 STMicroelectronics.
  * All rights reserved.
  *
  * This software is licensed under terms that can be found in the LICENSE file
  * in the root directory of this software component.
  * If no LICENSE file comes with this software, it is provided AS-IS.
  *
  ******************************************************************************
  */
/* USER CODE END Header */
#include "main.h"
#include "FreeRTOS.h"
#include "cmsis_os2.h"
#include "adc.h"
#include "bdma.h"
#include "dac.h"
#include "dma.h"
#include "fatfs.h"
#include "fdcan.h"
#include "mdma.h"
#include "octospi.h"
#include "ramecc.h"
#include "rtc.h"
#include "tim.h"
#include "usart.h"
#include "gpio.h"

/* USER CODE BEGIN Includes */
#include "SEGGER_RTT.h"
#include "SEGGER_SYSVIEW.h"
#include "sdmmc.h"
/* USER CODE END Includes */

/* USER CODE BEGIN PV */
CAN_Decoded_Values bms_fault;
/* USER CODE END PV */

void SystemClock_Config(void);
static void MPU_Config(void);
void MX_FREERTOS_Init(void);
/* USER CODE BEGIN PFP */
extern CAN_Decoded_Values Get_Signal(uint16_t id, uint8_t index);
/* USER CODE END PFP */

int main(void)
{

  /* USER CODE BEGIN 1 */
  CAN_Decoded_Values bms_fault;
  /* USER CODE END 1 */

  /* MPU Configuration--------------------------------------------------------*/
  MPU_Config();

  /* MCU Configuration--------------------------------------------------------*/

  /* Reset of all peripherals, Initializes the Flash interface and the Systick. */
  HAL_Init();

  /* Configure the system clock */
  SystemClock_Config();

  /* Initialize all configured peripherals */
  MX_GPIO_Init();
  MX_MDMA_Init();
  MX_DMA_Init();
  MX_BDMA_Init();
  MX_ADC1_Init();
  MX_FDCAN1_Init();
  MX_FDCAN2_Init();
  MX_FDCAN3_Init();
  MX_TIM1_Init();
  MX_TIM2_Init();
  MX_TIM4_Init();
  MX_TIM15_Init();
  MX_RAMECC_Init();
  MX_USART2_UART_Init();
  MX_ADC2_Init();
  MX_ADC3_Init();
  MX_TIM12_Init();
  MX_DAC1_Init();
  MX_TIM13_Init();
  MX_TIM14_Init();
  MX_FATFS_Init();
  MX_RTC_Init();
  MX_OCTOSPI1_Init();
  MX_TIM23_Init();
  MX_TIM24_Init();
  MX_TIM5_Init();
  /* USER CODE BEGIN 2 */

  //startup info

  //Lamp check (E.V. 6.3) page 101
  HAL_GPIO_WritePin(GPIOA, DigOut_2_Pin, GPIO_PIN_SET); //Highside driver for the lights
  HAL_Delay(2500);
  HAL_GPIO_WritePin(GPIOA, DigOut_2_Pin, GPIO_PIN_RESET);

  HAL_GPIO_WritePin(GPIOC, DigOut_4_Pin, GPIO_PIN_SET); //Power for fault latch
  HAL_Delay(5000); //wait for 5 seconds

  //get bms_fault
  bms_fault = Get_Signal(0x16, 3);
  while(bms_fault.uint8 > 0){
    //infinite loop until bms unfaults
    bms_fault = Get_Signal(0x16, 3);
  }

  SEGGER_RTT_Init();
  SEGGER_SYSVIEW_Conf();
  MX_SDMMC1_SD_Init();
  HAL_TIM_IC_Start_IT(&htim4, TIM_CHANNEL_1); //fl ws
  HAL_TIM_IC_Start_IT(&htim4, TIM_CHANNEL_2); //fr ws
  HAL_TIM_IC_Start_IT(&htim4, TIM_CHANNEL_3); //rl ws
  HAL_TIM_IC_Start_IT(&htim4, TIM_CHANNEL_4); //rr ws
  //flowrate timer
  __HAL_TIM_URS_ENABLE(&htim5);
  __HAL_TIM_CLEAR_FLAG(&htim5, TIM_FLAG_UPDATE);
  HAL_TIM_IC_Start(&htim5, TIM_CHANNEL_1);
  /* USER CODE END 2 */

  /* Init scheduler */
  osKernelInitialize();  /* Call init function for freertos objects (in cmsis_os2.c) */
  MX_FREERTOS_Init();

  /* Start scheduler */
  osKernelStart();

  /* We should never get here as control is now taken by the scheduler */

  /* Infinite loop */
  while(1)
  {

  }
}

void SystemClock_Config(void)
{
  RCC_OscInitTypeDef RCC_OscInitStruct = {0};
  RCC_ClkInitTypeDef RCC_ClkInitStruct = {0};

  /** Supply configuration update enable
  */
  HAL_PWREx_ConfigSupply(PWR_LDO_SUPPLY);

  /** Configure the main internal regulator output voltage
  */
  __HAL_PWR_VOLTAGESCALING_CONFIG(PWR_REGULATOR_VOLTAGE_SCALE0);

  while(!__HAL_PWR_GET_FLAG(PWR_FLAG_VOSRDY)) {}

  /** Initializes the RCC Oscillators according to the specified parameters
  * in the RCC_OscInitTypeDef structure.
  */
  RCC_OscInitStruct.OscillatorType = RCC_OSCILLATORTYPE_HSI|RCC_OSCILLATORTYPE_LSI;
  RCC_OscInitStruct.HSIState = RCC_HSI_DIV1;
  RCC_OscInitStruct.HSICalibrationValue = 64;
  RCC_OscInitStruct.LSIState = RCC_LSI_ON;
  RCC_OscInitStruct.PLL.PLLState = RCC_PLL_ON;
  RCC_OscInitStruct.PLL.PLLSource = RCC_PLLSOURCE_HSI;
  RCC_OscInitStruct.PLL.PLLM = 4;
  RCC_OscInitStruct.PLL.PLLN = 15;
  RCC_OscInitStruct.PLL.PLLP = 1;
  RCC_OscInitStruct.PLL.PLLQ = 3;
  RCC_OscInitStruct.PLL.PLLR = 2;
  RCC_OscInitStruct.PLL.PLLRGE = RCC_PLL1VCIRANGE_3;
  RCC_OscInitStruct.PLL.PLLVCOSEL = RCC_PLL1VCOWIDE;
  RCC_OscInitStruct.PLL.PLLFRACN = 0;
  if (HAL_RCC_OscConfig(&RCC_OscInitStruct) != HAL_OK)
  {
    Error_Handler();
  }

  /** Initializes the CPU, AHB and APB buses clocks
  */
  RCC_ClkInitStruct.ClockType = RCC_CLOCKTYPE_HCLK|RCC_CLOCKTYPE_SYSCLK
                              |RCC_CLOCKTYPE_PCLK1|RCC_CLOCKTYPE_PCLK2
                              |RCC_CLOCKTYPE_D3PCLK1|RCC_CLOCKTYPE_D1PCLK1;
  RCC_ClkInitStruct.SYSCLKSource = RCC_SYSCLKSOURCE_PLLCLK;
  RCC_ClkInitStruct.SYSCLKDivider = RCC_SYSCLK_DIV1;
  RCC_ClkInitStruct.AHBCLKDivider = RCC_HCLK_DIV1;
  RCC_ClkInitStruct.APB3CLKDivider = RCC_APB3_DIV2;
  RCC_ClkInitStruct.APB1CLKDivider = RCC_APB1_DIV2;
  RCC_ClkInitStruct.APB2CLKDivider = RCC_APB2_DIV2;
  RCC_ClkInitStruct.APB4CLKDivider = RCC_APB4_DIV2;

  if (HAL_RCC_ClockConfig(&RCC_ClkInitStruct, FLASH_LATENCY_3) != HAL_OK)
  {
    Error_Handler();
  }
}

/* USER CODE BEGIN 4 */

/// @brief Extracts bits from a starting point and takes defined amount
/// @param data data that needs to be extracted from
/// @param start_bit starting bit that wants to be extracted from data
/// @param size number of bits that are going to be extracted
/// @return Desired bits
uint64_t extract_bits(uint64_t data, uint8_t start_bit, uint8_t size){
  if(size == 0 || size > 64 || start_bit > 63 || (start_bit + size) > 64){
    return 0;
  }

  uint64_t mask = (size == 64) ? UINT64_MAX : ((1ULL << size) - 1);
  return (data >> start_bit) & mask;
}

/* USER CODE END 4 */

 /* MPU Configuration */

void MPU_Config(void)
{
  MPU_Region_InitTypeDef MPU_InitStruct = {0};

  /* Disables the MPU */
  HAL_MPU_Disable();

  /** Initializes and configures the Region and the memory to be protected
  */
  MPU_InitStruct.Enable = MPU_REGION_ENABLE;
  MPU_InitStruct.Number = MPU_REGION_NUMBER0;
  MPU_InitStruct.BaseAddress = 0x0;
  MPU_InitStruct.Size = MPU_REGION_SIZE_4GB;
  MPU_InitStruct.SubRegionDisable = 0x87;
  MPU_InitStruct.TypeExtField = MPU_TEX_LEVEL0;
  MPU_InitStruct.AccessPermission = MPU_REGION_FULL_ACCESS;
  MPU_InitStruct.DisableExec = MPU_INSTRUCTION_ACCESS_DISABLE;
  MPU_InitStruct.IsShareable = MPU_ACCESS_SHAREABLE;
  MPU_InitStruct.IsCacheable = MPU_ACCESS_CACHEABLE;
  MPU_InitStruct.IsBufferable = MPU_ACCESS_NOT_BUFFERABLE;

  HAL_MPU_ConfigRegion(&MPU_InitStruct);
  /* Enables the MPU */
  HAL_MPU_Enable(MPU_PRIVILEGED_DEFAULT);

}

void HAL_TIM_PeriodElapsedCallback(TIM_HandleTypeDef *htim)
{
  if (htim->Instance == TIM17)
  {
    HAL_IncTick();
  }
}

void Error_Handler(void)
{
  __disable_irq();
  while (1)
  {
  }
}

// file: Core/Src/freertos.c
/* USER CODE BEGIN Header */
/**
  ******************************************************************************
  * File Name          : freertos.c
  * Description        : Code for freertos applications
  ******************************************************************************
  * @attention
  *
  * Copyright (c) 2026 STMicroelectronics.
  * All rights reserved.
  *
  * This software is licensed under terms that can be found in the LICENSE file
  * in the root directory of this software component.
  * If no LICENSE file comes with this software, it is provided AS-IS.
  *
  ******************************************************************************
  */
/* USER CODE END Header */

#include "FreeRTOS.h"
#include "task.h"
#include "main.h"
#include "FreeRTOS.h"
#include "cmsis_os2.h"

/* USER CODE BEGIN Includes */
#include "fdcan.h"
#include "adc.h"
#include "tim.h"
#include "gpio.h"
#include "fatfs.h"
#include "ff.h"
#include "rtc.h"

extern DBC_Translation Assign_Signal(CAN_Msg_Raw *msg);
/* USER CODE END Includes */

typedef StaticTask_t osStaticThreadDef_t;
typedef StaticQueue_t osStaticMessageQDef_t;
typedef StaticSemaphore_t osStaticMutexDef_t;
typedef StaticSemaphore_t osStaticSemaphoreDef_t;
typedef StaticEventGroup_t osStaticEventGroupDef_t;
/* USER CODE BEGIN PTD */

typedef struct {
  uint32_t timestamp;

  uint32_t sus_fl;
  uint32_t sus_fr;
  uint32_t sus_bl;
  uint32_t sus_br;

  uint32_t throttle_pos;
  uint32_t apps2;

  uint32_t steering_ang;

  uint32_t inlet_temp;
  uint32_t outlet_temp;

  uint32_t f_brake_press;
  uint32_t b_brake_press;

  CAN_Decoded_Values BMS_1;
  CAN_Decoded_Values BMS_2;

  CAN_Decoded_Values DTI_1;
  CAN_Decoded_Values DTI_2;
  CAN_Decoded_Values DTI_3;
  CAN_Decoded_Values DTI_4;
  CAN_Decoded_Values DTI_5;

  CAN_Decoded_Values COOL_IN;
  CAN_Decoded_Values COOL_OUT;
  CAN_Decoded_Values COOL_FLOW;

  CAN_Decoded_Values BRAKE_PSI;

  CAN_Decoded_Values WHEEL1;
  CAN_Decoded_Values WHEEL2;

  CAN_Decoded_Values ROTOR1;
  CAN_Decoded_Values ROTOR2;
} TelemetryData_t;

typedef enum{
  Eco,
  Normal,
  Sport
}Powermodes;
/* USER CODE END PTD */

/* USER CODE BEGIN PD */
#define D3_RAM __attribute__((section(".D3_RAM")))
#define D2_RAM __attribute__((section(".D2_RAM")))
#define D1_RAM __attribute__((section(".D1_RAM")))
/* USER CODE END PD */

/* USER CODE BEGIN PM */
#define RTD_ON                BIT0
#define RTD_BUZZ              BIT1
#define RTD_BUTT              BIT2
#define RTD_FAULT             BIT3
#define MC_MAX_OUTPUT         500
/* USER CODE END PM */

/* USER CODE BEGIN Variables */
extern TIM_HandleTypeDef htim1;
extern ADC_HandleTypeDef hadc1;
extern FATFS SDFatFS;

volatile D2_RAM uint32_t adc12_dma_buf[ADC12_BUFFER_COUNT];
volatile D3_RAM uint16_t adc3_dma_buf[ADC3_BUFFER_COUNT];

volatile uint32_t test_reading;
volatile uint32_t pump_speed;

D1_RAM char sd_write_buffer[512] __attribute((aligned(32)));

D1_RAM FIL LogFile;

static volatile Powermodes power;

//sigmoid function
static const uint16_t throttle_curve[11] = {
0, 302, 519, 707, 881, 1050, 1219, 1393, 1581, 1798, 2100
};

static uint8_t max_perc = 80;

/* USER CODE END Variables */
/* Definitions for defaultTask */
osThreadId_t defaultTaskHandle;
const osThreadAttr_t defaultTask_attributes = {
  .name = "defaultTask",
  .stack_size = 128 * 4,
  .priority = (osPriority_t) osPriorityNormal,
};
/* Definitions for ADCTask */
osThreadId_t ADCTaskHandle;
uint32_t ADCTaskBuffer[ 256 ];
osStaticThreadDef_t ADCTaskControlBlock;
const osThreadAttr_t ADCTask_attributes = {
  .name = "ADCTask",
  .cb_mem = &ADCTaskControlBlock,
  .cb_size = sizeof(ADCTaskControlBlock),
  .stack_mem = &ADCTaskBuffer[0],
  .stack_size = sizeof(ADCTaskBuffer),
  .priority = (osPriority_t) osPriorityAboveNormal3,
};
/* Definitions for DecodeCAN2 */
osThreadId_t DecodeCAN2Handle;
uint32_t DecodeCAN2Buffer[ 1024 ];
osStaticThreadDef_t DecodeCAN2ControlBlock;
const osThreadAttr_t DecodeCAN2_attributes = {
  .name = "DecodeCAN2",
  .cb_mem = &DecodeCAN2ControlBlock,
  .cb_size = sizeof(DecodeCAN2ControlBlock),
  .stack_mem = &DecodeCAN2Buffer[0],
  .stack_size = sizeof(DecodeCAN2Buffer),
  .priority = (osPriority_t) osPriorityBelowNormal2,
};
/* Definitions for DecodeCAN1 */
osThreadId_t DecodeCAN1Handle;
uint32_t DecodeCAN1Buffer[ 1024 ];
osStaticThreadDef_t DecodeCAN1ControlBlock;
const osThreadAttr_t DecodeCAN1_attributes = {
  .name = "DecodeCAN1",
  .cb_mem = &DecodeCAN1ControlBlock,
  .cb_size = sizeof(DecodeCAN1ControlBlock),
  .stack_mem = &DecodeCAN1Buffer[0],
  .stack_size = sizeof(DecodeCAN1Buffer),
  .priority = (osPriority_t) osPriorityAboveNormal5,
};
/* Definitions for CreateMsgCAN1 */
osThreadId_t CreateMsgCAN1Handle;
uint32_t CreateMsgCAN1Buffer[ 1024 ];
osStaticThreadDef_t CreateMsgCAN1ControlBlock;
const osThreadAttr_t CreateMsgCAN1_attributes = {
  .name = "CreateMsgCAN1",
  .cb_mem = &CreateMsgCAN1ControlBlock,
  .cb_size = sizeof(CreateMsgCAN1ControlBlock),
  .stack_mem = &CreateMsgCAN1Buffer[0],
  .stack_size = sizeof(CreateMsgCAN1Buffer),
  .priority = (osPriority_t) osPriorityAboveNormal4,
};
/* Definitions for CreateMsgCAN2 */
osThreadId_t CreateMsgCAN2Handle;
uint32_t CreateMsgCAN2Buffer[ 1024 ];
osStaticThreadDef_t CreateMsgCAN2ControlBlock;
const osThreadAttr_t CreateMsgCAN2_attributes = {
  .name = "CreateMsgCAN2",
  .cb_mem = &CreateMsgCAN2ControlBlock,
  .cb_size = sizeof(CreateMsgCAN2ControlBlock),
  .stack_mem = &CreateMsgCAN2Buffer[0],
  .stack_size = sizeof(CreateMsgCAN2Buffer),
  .priority = (osPriority_t) osPriorityLow,
};
/* Definitions for PWMTask */
osThreadId_t PWMTaskHandle;
uint32_t PWMTaskBuffer[ 128 ];
osStaticThreadDef_t PWMTaskControlBlock;
const osThreadAttr_t PWMTask_attributes = {
  .name = "PWMTask",
  .cb_mem = &PWMTaskControlBlock,
  .cb_size = sizeof(PWMTaskControlBlock),
  .stack_mem = &PWMTaskBuffer[0],
  .stack_size = sizeof(PWMTaskBuffer),
  .priority = (osPriority_t) osPriorityNormal4,
};
/* Definitions for LoggingTask */
osThreadId_t LoggingTaskHandle;
uint32_t LoggingTaskBuffer[ 1024 ];
osStaticThreadDef_t LoggingTaskControlBlock;
const osThreadAttr_t LoggingTask_attributes = {
  .name = "LoggingTask",
  .cb_mem = &LoggingTaskControlBlock,
  .cb_size = sizeof(LoggingTaskControlBlock),
  .stack_mem = &LoggingTaskBuffer[0],
  .stack_size = sizeof(LoggingTaskBuffer),
  .priority = (osPriority_t) osPriorityLow1,
};
/* Definitions for GPIOTask */
osThreadId_t GPIOTaskHandle;
uint32_t GPIOTaskBuffer[ 128 ];
osStaticThreadDef_t GPIOTaskControlBlock;
const osThreadAttr_t GPIOTask_attributes = {
  .name = "GPIOTask",
  .cb_mem = &GPIOTaskControlBlock,
  .cb_size = sizeof(GPIOTaskControlBlock),
  .stack_mem = &GPIOTaskBuffer[0],
  .stack_size = sizeof(GPIOTaskBuffer),
  .priority = (osPriority_t) osPriorityNormal3,
};
/* Definitions for RTDSM */
osThreadId_t RTDSMHandle;
uint32_t RTDSMBuffer[ 128 ];
osStaticThreadDef_t RTDSMControlBlock;
const osThreadAttr_t RTDSM_attributes = {
  .name = "RTDSM",
  .cb_mem = &RTDSMControlBlock,
  .cb_size = sizeof(RTDSMControlBlock),
  .stack_mem = &RTDSMBuffer[0],
  .stack_size = sizeof(RTDSMBuffer),
  .priority = (osPriority_t) osPriorityRealtime7,
};
/* Definitions for RTDOn */
osThreadId_t RTDOnHandle;
uint32_t RTDOnBuffer[ 128 ];
osStaticThreadDef_t RTDOnControlBlock;
const osThreadAttr_t RTDOn_attributes = {
  .name = "RTDOn",
  .cb_mem = &RTDOnControlBlock,
  .cb_size = sizeof(RTDOnControlBlock),
  .stack_mem = &RTDOnBuffer[0],
  .stack_size = sizeof(RTDOnBuffer),
  .priority = (osPriority_t) osPriorityRealtime5,
};
/* Definitions for TelemLog */
osThreadId_t TelemLogHandle;
uint32_t TelemLogBuffer[ 256 ];
osStaticThreadDef_t TelemLogControlBlock;
const osThreadAttr_t TelemLog_attributes = {
  .name = "TelemLog",
  .cb_mem = &TelemLogControlBlock,
  .cb_size = sizeof(TelemLogControlBlock),
  .stack_mem = &TelemLogBuffer[0],
  .stack_size = sizeof(TelemLogBuffer),
  .priority = (osPriority_t) osPriorityLow,
};
/* Definitions for CAN1rxQ */
osMessageQueueId_t CAN1rxQHandle;
uint8_t CAN1rxQBuffer[ 16 * sizeof( CAN_Msg_Raw ) ];
osStaticMessageQDef_t CAN1rxQControlBlock;
const osMessageQueueAttr_t CAN1rxQ_attributes = {
  .name = "CAN1rxQ",
  .cb_mem = &CAN1rxQControlBlock,
  .cb_size = sizeof(CAN1rxQControlBlock),
  .mq_mem = &CAN1rxQBuffer,
  .mq_size = sizeof(CAN1rxQBuffer)
};
/* Definitions for CAN1txQ */
osMessageQueueId_t CAN1txQHandle;
uint8_t CAN1txQBuffer[ 8 * sizeof( CAN_Msg_Raw ) ];
osStaticMessageQDef_t CAN1txQControlBlock;
const osMessageQueueAttr_t CAN1txQ_attributes = {
  .name = "CAN1txQ",
  .cb_mem = &CAN1txQControlBlock,
  .cb_size = sizeof(CAN1txQControlBlock),
  .mq_mem = &CAN1txQBuffer,
  .mq_size = sizeof(CAN1txQBuffer)
};
/* Definitions for CAN2rxQ */
osMessageQueueId_t CAN2rxQHandle;
uint8_t CAN2rxQBuffer[ 24 * sizeof( CAN_Msg_Raw ) ];
osStaticMessageQDef_t CAN2rxQControlBlock;
const osMessageQueueAttr_t CAN2rxQ_attributes = {
  .name = "CAN2rxQ",
  .cb_mem = &CAN2rxQControlBlock,
  .cb_size = sizeof(CAN2rxQControlBlock),
  .mq_mem = &CAN2rxQBuffer,
  .mq_size = sizeof(CAN2rxQBuffer)
};
/* Definitions for CAN2txQ */
osMessageQueueId_t CAN2txQHandle;
uint8_t CAN2txQBuffer[ 16 * sizeof( CAN_Msg_Raw ) ];
osStaticMessageQDef_t CAN2txQControlBlock;
const osMessageQueueAttr_t CAN2txQ_attributes = {
  .name = "CAN2txQ",
  .cb_mem = &CAN2txQControlBlock,
  .cb_size = sizeof(CAN2txQControlBlock),
  .mq_mem = &CAN2txQBuffer,
  .mq_size = sizeof(CAN2txQBuffer)
};
/* Definitions for ADCLogQ */
osMessageQueueId_t ADCLogQHandle;
uint8_t ADCLogQBuffer[ 64 * sizeof( TelemetryData_t ) ];
osStaticMessageQDef_t ADCLogQControlBlock;
const osMessageQueueAttr_t ADCLogQ_attributes = {
  .name = "ADCLogQ",
  .cb_mem = &ADCLogQControlBlock,
  .cb_size = sizeof(ADCLogQControlBlock),
  .mq_mem = &ADCLogQBuffer,
  .mq_size = sizeof(ADCLogQBuffer)
};
/* Definitions for CANLogQ */
osMessageQueueId_t CANLogQHandle;
uint8_t CANLogQBuffer[ 16 * sizeof( TelemetryData_t ) ];
osStaticMessageQDef_t CANLogQControlBlock;
const osMessageQueueAttr_t CANLogQ_attributes = {
  .name = "CANLogQ",
  .cb_mem = &CANLogQControlBlock,
  .cb_size = sizeof(CANLogQControlBlock),
  .mq_mem = &CANLogQBuffer,
  .mq_size = sizeof(CANLogQBuffer)
};
/* Definitions for CAN1txM */
osMutexId_t CAN1txMHandle;
osStaticMutexDef_t CAN1txMControlBlock;
const osMutexAttr_t CAN1txM_attributes = {
  .name = "CAN1txM",
  .cb_mem = &CAN1txMControlBlock,
  .cb_size = sizeof(CAN1txMControlBlock),
};
/* Definitions for CAN2txM */
osMutexId_t CAN2txMHandle;
osStaticMutexDef_t CAN2txMControlBlock;
const osMutexAttr_t CAN2txM_attributes = {
  .name = "CAN2txM",
  .cb_mem = &CAN2txMControlBlock,
  .cb_size = sizeof(CAN2txMControlBlock),
};
/* Definitions for CAN1rxS */
osSemaphoreId_t CAN1rxSHandle;
osStaticSemaphoreDef_t CAN1rxSControlBlock;
const osSemaphoreAttr_t CAN1rxS_attributes = {
  .name = "CAN1rxS",
  .cb_mem = &CAN1rxSControlBlock,
  .cb_size = sizeof(CAN1rxSControlBlock),
};
/* Definitions for CAN1txS */
osSemaphoreId_t CAN1txSHandle;
osStaticSemaphoreDef_t CAN1txSControlBlock;
const osSemaphoreAttr_t CAN1txS_attributes = {
  .name = "CAN1txS",
  .cb_mem = &CAN1txSControlBlock,
  .cb_size = sizeof(CAN1txSControlBlock),
};
/* Definitions for CAN2rxS */
osSemaphoreId_t CAN2rxSHandle;
osStaticSemaphoreDef_t CAN2rxSControlBlock;
const osSemaphoreAttr_t CAN2rxS_attributes = {
  .name = "CAN2rxS",
  .cb_mem = &CAN2rxSControlBlock,
  .cb_size = sizeof(CAN2rxSControlBlock),
};
/* Definitions for CAN2txS */
osSemaphoreId_t CAN2txSHandle;
osStaticSemaphoreDef_t CAN2txSControlBlock;
const osSemaphoreAttr_t CAN2txS_attributes = {
  .name = "CAN2txS",
  .cb_mem = &CAN2txSControlBlock,
  .cb_size = sizeof(CAN2txSControlBlock),
};
/* Definitions for VCUGroupEvent */
osEventFlagsId_t VCUGroupEventHandle;
osStaticEventGroupDef_t VCUGroupEventControlBlock;
const osEventFlagsAttr_t VCUGroupEvent_attributes = {
  .name = "VCUGroupEvent",
  .cb_mem = &VCUGroupEventControlBlock,
  .cb_size = sizeof(VCUGroupEventControlBlock),
};
/* Definitions for RTD */
osEventFlagsId_t RTDHandle;
osStaticEventGroupDef_t RTDControlBlock;
const osEventFlagsAttr_t RTD_attributes = {
  .name = "RTD",
  .cb_mem = &RTDControlBlock,
  .cb_size = sizeof(RTDControlBlock),
};

void StartDefaultTask(void *argument);
void StartADCTask(void *argument);
void StartDecodeCAN2(void *argument);
void StartDecodeCAN1(void *argument);
void StartCreateMsgCAN1(void *argument);
void StartCreateMsgCAN2(void *argument);
void StartPWMTask(void *argument);
void StartLoggingTask(void *argument);
void StartTaskGPIO(void *argument);
void StartRTDSM(void *argument);
void StartRTDOn(void *argument);
void StartTelemLog(void *argument);

void MX_FREERTOS_Init(void); /* (MISRA C 2004 rule 8.1) */

void MX_FREERTOS_Init(void) {
  /* USER CODE BEGIN Init */
  //Creation of Event group
  /* USER CODE END Init */
  /* Create the mutex(es) */
  /* creation of CAN1txM */
  CAN1txMHandle = osMutexNew(&CAN1txM_attributes);

  /* creation of CAN2txM */
  CAN2txMHandle = osMutexNew(&CAN2txM_attributes);

  /* Create the semaphores(s) */
  /* creation of CAN1rxS */
  CAN1rxSHandle = osSemaphoreNew(1, 1, &CAN1rxS_attributes);

  /* creation of CAN1txS */
  CAN1txSHandle = osSemaphoreNew(1, 1, &CAN1txS_attributes);

  /* creation of CAN2rxS */
  CAN2rxSHandle = osSemaphoreNew(1, 1, &CAN2rxS_attributes);

  /* creation of CAN2txS */
  CAN2txSHandle = osSemaphoreNew(1, 1, &CAN2txS_attributes);

  /* Create the queue(s) */
  /* creation of CAN1rxQ */
  CAN1rxQHandle = osMessageQueueNew (16, sizeof(CAN_Msg_Raw), &CAN1rxQ_attributes);

  /* creation of CAN1txQ */
  CAN1txQHandle = osMessageQueueNew (8, sizeof(CAN_Msg_Raw), &CAN1txQ_attributes);

  /* creation of CAN2rxQ */
  CAN2rxQHandle = osMessageQueueNew (24, sizeof(CAN_Msg_Raw), &CAN2rxQ_attributes);

  /* creation of CAN2txQ */
  CAN2txQHandle = osMessageQueueNew (16, sizeof(CAN_Msg_Raw), &CAN2txQ_attributes);

  /* creation of ADCLogQ */
  ADCLogQHandle = osMessageQueueNew (64, sizeof(TelemetryData_t), &ADCLogQ_attributes);

  /* creation of CANLogQ */
  CANLogQHandle = osMessageQueueNew (16, sizeof(TelemetryData_t), &CANLogQ_attributes);

  /* Create the thread(s) */
  /* creation of defaultTask */
  defaultTaskHandle = osThreadNew(StartDefaultTask, NULL, &defaultTask_attributes);

  /* creation of ADCTask */
  ADCTaskHandle = osThreadNew(StartADCTask, NULL, &ADCTask_attributes);

  /* creation of DecodeCAN2 */
  DecodeCAN2Handle = osThreadNew(StartDecodeCAN2, NULL, &DecodeCAN2_attributes);

  /* creation of DecodeCAN1 */
  DecodeCAN1Handle = osThreadNew(StartDecodeCAN1, NULL, &DecodeCAN1_attributes);

  /* creation of CreateMsgCAN1 */
  CreateMsgCAN1Handle = osThreadNew(StartCreateMsgCAN1, NULL, &CreateMsgCAN1_attributes);

  /* creation of CreateMsgCAN2 */
  CreateMsgCAN2Handle = osThreadNew(StartCreateMsgCAN2, NULL, &CreateMsgCAN2_attributes);

  /* creation of PWMTask */
  PWMTaskHandle = osThreadNew(StartPWMTask, NULL, &PWMTask_attributes);

  /* creation of LoggingTask */
  LoggingTaskHandle = osThreadNew(StartLoggingTask, NULL, &LoggingTask_attributes);

  /* creation of GPIOTask */
  GPIOTaskHandle = osThreadNew(StartTaskGPIO, NULL, &GPIOTask_attributes);

  /* creation of RTDSM */
  RTDSMHandle = osThreadNew(StartRTDSM, NULL, &RTDSM_attributes);

  /* creation of RTDOn */
  RTDOnHandle = osThreadNew(StartRTDOn, NULL, &RTDOn_attributes);

  /* creation of TelemLog */
  TelemLogHandle = osThreadNew(StartTelemLog, NULL, &TelemLog_attributes);

  /* creation of VCUGroupEvent */
  VCUGroupEventHandle = osEventFlagsNew(&VCUGroupEvent_attributes);

  /* creation of RTD */
  RTDHandle = osEventFlagsNew(&RTD_attributes);

}

void StartDefaultTask(void *argument)
{
  for(;;)
  {
  osDelay(1);
  }
}

void StartADCTask(void *argument)
{
  /* USER CODE BEGIN StartADCTask */

  HAL_ADCEx_Calibration_Start(&hadc1, ADC_CALIB_OFFSET, ADC_SINGLE_ENDED);
  HAL_ADCEx_Calibration_Start(&hadc3, ADC_CALIB_OFFSET, ADC_SINGLE_ENDED);

  HAL_TIM_Base_Start(&htim1);

  TelemetryData_t adcData;

  uint8_t can_data[8] = {0};
  uint8_t perc = 0;
  /* Infinite loop */
  for(;;)
  {
    HAL_ADCEx_MultiModeStart_DMA(&hadc1, (uint32_t*) adc12_dma_buf, ADC12_BUFFER_COUNT);
    HAL_ADC_Start_DMA(&hadc3, (uint32_t*) adc3_dma_buf, ADC3_BUFFER_COUNT);

    sus_fl.avg = (sus_fl.data1 + sus_fl.data2) / 2;
    sus_fr.avg = (sus_fr.data1 + sus_fr.data2) / 2;
    sus_bl.avg = (sus_bl.data1 + sus_bl.data2) / 2;
    sus_br.avg = (sus_br.data1 + sus_br.data2) / 2;

    steering_ang.avg = (steering_ang.data1 + steering_ang.data2) / 2;

    throttle_pos.avg = (throttle_pos.data1 + throttle_pos.data2) / 2;
    apps2.avg = apps2.data1;

  //APPS check
  uint32_t high = (throttle_pos.avg > apps2.avg) ? throttle_pos.data1 : apps2.avg;
  uint32_t low = (throttle_pos.avg > apps2.avg) ? apps2.avg : throttle_pos.avg;
  uint64_t diff= high - low;
    if(osEventFlagsGet(RTDHandle) & RTD_ON && !(diff * 10 > high)){
      if(throttle_pos.avg >= throttle_curve[10]){
        perc = 100;
      }
      else if(throttle_pos.avg <= throttle_curve[0]){
        perc = 0;
      }
      else{
        for(uint8_t i = 1; i < 10; i++){
          if(throttle_pos.avg <= throttle_curve[i]){
            //left side of the equation finds the tens position of the percentage while the right finds the ones position
            perc = ((i - 1) * 10) + ((throttle_pos.avg - throttle_curve[i-1]) / (throttle_curve[i] - throttle_curve[i-1]));
          }
        }
      }
      perc = ((uint8_t) (perc * Traction_Control())) * 10 ;
      can_data[0] = (uint8_t) (perc & 0xFF);
      can_data[1] = (uint8_t) ((perc >> 8) & 0xFF);

      Prepare_Message(&hfdcan1, 0x05, can_data, 2); //for relative output current (find real id)
  }
  else{
    osEventFlagsSet(RTDHandle, RTD_FAULT);
  }

    inlet_temp.avg = (inlet_temp.data1 + inlet_temp.data2) / 2;
    outlet_temp.avg = (outlet_temp.data1 + outlet_temp.data2) / 2;

    f_brake_press.avg = (f_brake_press.data1 + f_brake_press.data2) / 2;
    b_brake_press.avg = (b_brake_press.data1 + b_brake_press.data2) / 2;

  //BSPD check
  if(throttle_pos.avg>= HARD_ACCEL && b_brake_press.avg>= HARD_BRAKE){
    osEventFlagsSet(RTDHandle, RTD_FAULT);
  }

    //put actual brake light pin
    if((f_brake_press.avg + b_brake_press.avg)/2 >= BRAKE_ON){
      HAL_GPIO_WritePin(GPIOA, DigOut_3_Pin, GPIO_PIN_SET);
    }
    else{
      HAL_GPIO_WritePin(GPIOA, DigOut_3_Pin, GPIO_PIN_RESET);
    }

    adcData.timestamp = HAL_GetTick();

    adcData.sus_fl = sus_fl.avg;
    adcData.sus_fr = sus_fr.avg;
    adcData.sus_bl = sus_bl.avg;
    adcData.sus_br = sus_br.avg;

    adcData.throttle_pos = throttle_pos.avg;
    adcData.apps2 =  apps2.avg;

    adcData.steering_ang = steering_ang.avg;

    adcData.inlet_temp = inlet_temp.avg;
    adcData.outlet_temp = outlet_temp.avg;

    adcData.f_brake_press = f_brake_press.avg;
    adcData.b_brake_press = b_brake_press.avg;

    ulTaskNotifyTake(pdTRUE, portMAX_DELAY);

    osMessageQueuePut(ADCLogQHandle, &adcData, 0, osWaitForever);
  }
  /* USER CODE END StartADCTask */
}

void StartDecodeCAN2(void *argument)
{
  /* USER CODE BEGIN StartDecodeCAN2 */
  CAN_Msg_Raw msg_raw;
  DBC_Translation dbc;
  osStatus_t status;
  /* Infinite loop */
  for(;;)
  {
    osSemaphoreAcquire(CAN2rxSHandle, 0);
    status = osMessageQueueGet(CAN2rxQHandle, &msg_raw, NULL, osWaitForever); //change timeout later
    switch(status){
      case osOK:
        dbc = Assign_Signal(&msg_raw);
        Decode_Message(msg_raw, dbc);
        osSemaphoreRelease(CAN2rxSHandle);
      break;

      default:
      Error_Handler();
    }
    osDelay(1);
  }
  /* USER CODE END StartDecodeCAN2 */
}

void StartDecodeCAN1(void *argument)
{
  /* USER CODE BEGIN StartDecodeCAN1 */
  CAN_Msg_Raw msg_raw;
  DBC_Translation dbc;
  osStatus_t status;
  /* Infinite loop */
  for(;;)
  {
   osSemaphoreAcquire(CAN1rxSHandle, 0);
    status = osMessageQueueGet(CAN1rxQHandle, &msg_raw, NULL, osWaitForever);//change timeout later
    switch(status){
      case osOK:
        dbc = Assign_Signal(&msg_raw);
        Decode_Message(msg_raw, dbc);
        osSemaphoreRelease(CAN1rxSHandle);
      break;

      default:
      Error_Handler();
    }
    osDelay(1);
  }
  /* USER CODE END StartDecodeCAN1 */
}

void StartCreateMsgCAN1(void *argument)
{
  /* USER CODE BEGIN StartCreateMsgCAN1 */
  /* Infinite loop */
  for(;;)
  {
    //implement if needed
    osDelay(1);
  }
  /* USER CODE END StartCreateMsgCAN1 */
}

void StartCreateMsgCAN2(void *argument)
{
  /* USER CODE BEGIN StartCreateMsgCAN2 */
  /* Infinite loop */
  for(;;)
  {
    //implement if needed
    osDelay(1);
  }
  /* USER CODE END StartCreateMsgCAN2 */
}

void StartPWMTask(void *argument)
{
  /* USER CODE BEGIN StartPWMTask */
  HAL_TIM_PWM_Start(&htim2, TIM_CHANNEL_1);

  uint16_t pump_on = 250; // 250/1000 = 25% duty cycle
  uint16_t pump_off = 50; // 50/1000 = 5% duty cycle

  /* Infinite loop */
  for(;;)
  {
    test_reading = inlet_temp.avg;

    if (test_reading >= 50000) {
      pump_speed = pump_on;
    } else if (test_reading <= 10000) {
      pump_speed = pump_off;
    }

    __HAL_TIM_SET_COMPARE(&htim2, TIM_CHANNEL_1, pump_speed);
    osDelay(1);
  }
  /* USER CODE END StartPWMTask */
}

void StartLoggingTask(void *argument)
{
  /* USER CODE BEGIN StartLoggingTask */
  UINT bytesWritten;
  TelemetryData_t ADCData;
  TelemetryData_t CANData;
  RTC_TimeTypeDef time;
  RTC_DateTypeDef date;
  static char dirName[16];
  static char fileName[32];
  static uint8_t done = 0;
  uint8_t writeCtr = 0;

  // temporary
  TelemetryData_t temp;

  HAL_RTC_GetTime(&hrtc, &time, RTC_FORMAT_BIN);
  HAL_RTC_GetDate(&hrtc, &date, RTC_FORMAT_BIN);

  snprintf(dirName, sizeof(dirName), "%02u-%02u", date.Month, date.Date);

  FRESULT fRes = f_mount(&SDFatFS, "", 1);
  if (fRes != FR_OK) osThreadExit();

  // Uncomment this to test more than one log file
  fRes = f_mkdir(dirName);
  if (fRes != FR_OK && fRes != FR_EXIST) osThreadExit();

  fRes = f_chdir(dirName);
  if (fRes != FR_OK) osThreadExit();

  int i = 0;
  while (!done) {
    snprintf(fileName, sizeof(fileName), "log_%02u.csv", i);
    fRes = f_open(&LogFile, fileName, FA_CREATE_NEW | FA_WRITE);
    if (fRes == FR_OK) done = 1;
    else i++;
    if (i == 1000) break;
  }

  int len = snprintf(sd_write_buffer, sizeof(sd_write_buffer),
  "TIME, SUSPENSION FL, SUSPENSION FR, SUSPENSION BL, SUSPENSION BR, THROTTLE POSITION, APPS2, STEERING ANGLE, INLET TEMPERATURE, OUTLET TEMPERATURE, FRONT BRAKE PRESSURE, BACK BRAKE PRESSURE, BMS 1, BMS 2, DTI 1, DTI 2, DTI 3, DTI 4, DTI 5, COOLANT IN, COOLANT OUT, COOLANT FLOW, BRAKE PSI, WHEEL1, WHEEL2, ROTOR1, ROTOR2\n");
  f_write(&LogFile, &sd_write_buffer, len, &bytesWritten);
  /* Infinite loop */
  for(;;)
  {
    // replace all id's and indices as necessary
    temp.BMS_1 = Get_Signal(0x6B1, 0);
    temp.BMS_2 = Get_Signal(0x6B1, 1);
    temp.DTI_1 = Get_Signal(0x6B1, 0);
    temp.DTI_2 = Get_Signal(0x6B1, 1);
    temp.DTI_3 = Get_Signal(0x6B1, 2);
    temp.DTI_4 = Get_Signal(0x6B1, 3);
    temp.DTI_5 = Get_Signal(0x6B1, 4);
    temp.COOL_IN = Get_Signal(0x6B1, 0);
    temp.COOL_OUT = Get_Signal(0x6B1, 0);
    temp.COOL_FLOW = Get_Signal(0x6B1, 0);
    temp.BRAKE_PSI = Get_Signal(0x6B1, 0);
    temp.WHEEL1 = Get_Signal(0x6B1, 0);
    temp.WHEEL2 = Get_Signal(0x6B1, 0);
    temp.ROTOR1 = Get_Signal(0x6B1, 0);
    temp.ROTOR2 = Get_Signal(0x6B1, 0);

    temp.BMS_1.uint32 =  500;

    osMessageQueuePut(CANLogQHandle, &temp, 0, osWaitForever);

    writeCtr++;
    if (osMessageQueueGet(ADCLogQHandle, &ADCData, NULL, osWaitForever) == osOK && osMessageQueueGet(CANLogQHandle, &CANData, NULL, osWaitForever) == osOK) {
      len = snprintf(sd_write_buffer, sizeof(sd_write_buffer), "%lu, %lu, %lu, %lu, %lu, %lu, %lu, %lu, %lu, %lu, %lu, %lu,%lu, %lu, %lu, %lu, %lu, %lu, %lu, %lu, %lu, %lu, %lu, %lu, %lu, %lu, %lu\n",
      ADCData.timestamp,
      ADCData.sus_fl,
      ADCData.sus_fr,
      ADCData.sus_bl,
      ADCData.sus_br,
      ADCData.throttle_pos,
      ADCData.apps2,
      ADCData.steering_ang,
      ADCData.inlet_temp,
      ADCData.outlet_temp,
      ADCData.f_brake_press,
      ADCData.b_brake_press,
      CANData.BMS_1.uint32,
      CANData.BMS_2.uint32,
      CANData.DTI_1.uint32,
      CANData.DTI_2.uint32,
      CANData.DTI_3.uint32,
      CANData.DTI_4.uint32,
      CANData.DTI_5.uint32,
      CANData.COOL_IN.uint32,
      CANData.COOL_OUT.uint32,
      CANData.COOL_FLOW.uint32,
      CANData.BRAKE_PSI.uint32,
      CANData.WHEEL1.uint32,
      CANData.WHEEL2.uint32,
      CANData.ROTOR1.uint32,
      CANData.ROTOR2.uint32
    );

      if (f_write(&LogFile, &sd_write_buffer, len, &bytesWritten) == FR_OK) {
        if (writeCtr == 50) {
          fRes = f_sync(&LogFile);
          writeCtr = 0;
        }
      }

    }

    osDelay(1);
  }
  /* USER CODE END StartLoggingTask */
}

void StartTaskGPIO(void *argument)
{
  /* USER CODE BEGIN StartTaskGPIO */
  /* Infinite loop */
  EventBits_t uxBits;
  for (;;)
  {
    uxBits = xEventGroupWaitBits(
      VCUGroupEventHandle,
      (BTN_POWER_MODE|BTN_RTD|BTN_WATER_PUMP|BTN_HV_CHECK),
      pdTRUE,
      pdFALSE,
      portMAX_DELAY
    );

    if((uxBits & BTN_POWER_MODE) != 0){
      uint8_t can_data[2] = {0};
      int16_t data;

      //alt
      //power = (power + 1) % 3;
      switch(power){
        case Normal:
          power = Sport;
          data = MC_MAX_OUTPUT * 10; //max output
          max_perc = 100;

          break;

        case Sport:
          power = Eco;
          data = (int16_t)(MC_MAX_OUTPUT * .7) * 10; //70%
          max_perc = 70;
          break;

        case Eco:
          power = Normal;
          data = (int16_t)(MC_MAX_OUTPUT * .85) *10; //85%
          max_perc = 85;

          break;

        default:
          power = Normal;
          data = (int16_t)(MC_MAX_OUTPUT * .85) *10; //85%
          max_perc = 85;

      }

      can_data[0] = (uint8_t) (data & 0xFF);
      can_data[1] = (uint8_t)((data >> 8) & 0xFF);
      Prepare_Message(&hfdcan1, 0x08, can_data, 2); //sets max current based on motor controller max
    }

    if ((uxBits & BTN_HV_CHECK) != 0){

      //Check if were above 60V

        return;
    }

    if ((uxBits & BTN_RTD) !=0) {
      //pin not confirmed
      if(HAL_GPIO_ReadPin(GPIOE,GPIO_PIN_1)){
        osEventFlagsSet(RTDHandle, RTD_BUTT);
      }
      else{
        osEventFlagsClear(RTDHandle, 1);
      }
      //All tests should pass, if any failure we should then iniatiate a shutdow

    }

    if ((uxBits & BTN_WATER_PUMP) != 0){
      //Pass water through the system

        return;
    }
    osDelay(1);

  }
  /* USER CODE END StartTaskGPIO */
}

void StartRTDSM(void *argument)
{
  /* USER CODE BEGIN StartRTDSM */
  uint32_t flags;
  uint8_t can_data[8] = {0};
  /* Infinite loop */
  for(;;)
  {
    osEventFlagsWait(RTDHandle, RTD_BUZZ | RTD_FAULT, osFlagsWaitAny, osWaitForever);
    flags = osEventFlagsGet(RTDHandle);
    if(flags & RTD_FAULT){
      //CAN id for drive enable
      can_data[3] = 1; //turn off motor controller
      Prepare_Message(&hfdcan1,0x24,can_data,8);
      osEventFlagsClear(RTDHandle, RTD_ON);
    }
    else if(flags & RTD_BUZZ){
      // turn buzzer on for 1 second
      HAL_GPIO_WritePin(GPIOA,DigOut_1_Pin, GPIO_PIN_SET); //put actual buzzer pin when done implementing
      osDelay(1000);
      HAL_GPIO_WritePin(GPIOA,DigOut_1_Pin,GPIO_PIN_RESET);
      osEventFlagsClear(RTDHandle, RTD_BUZZ);

      can_data[3] = 0;
      // turn on motor controller
      Prepare_Message(&hfdcan1, 0x24, can_data, 8);
      osEventFlagsSet(RTDHandle, RTD_ON);
    }
    osDelay(1);
  }
  /* USER CODE END StartRTDSM */
}

void StartRTDOn(void *argument)
{
  /* USER CODE BEGIN StartRTDOn */
  //call from GPIO input from RTD button
  /* Infinite loop */
  for(;;)
  {
    osEventFlagsWait(RTDHandle,RTD_BUTT,osFlagsNoClear,osWaitForever);
    if((f_brake_press.avg + b_brake_press.avg)/2 >= BRAKE_ON){
      osEventFlagsSet(RTDHandle, RTD_BUZZ);
    }
    osDelay(1);
  }
  /* USER CODE END StartRTDOn */
}

void StartTelemLog(void *argument)
{
  for(;;)
  {
    osDelay(1);
  }
}
